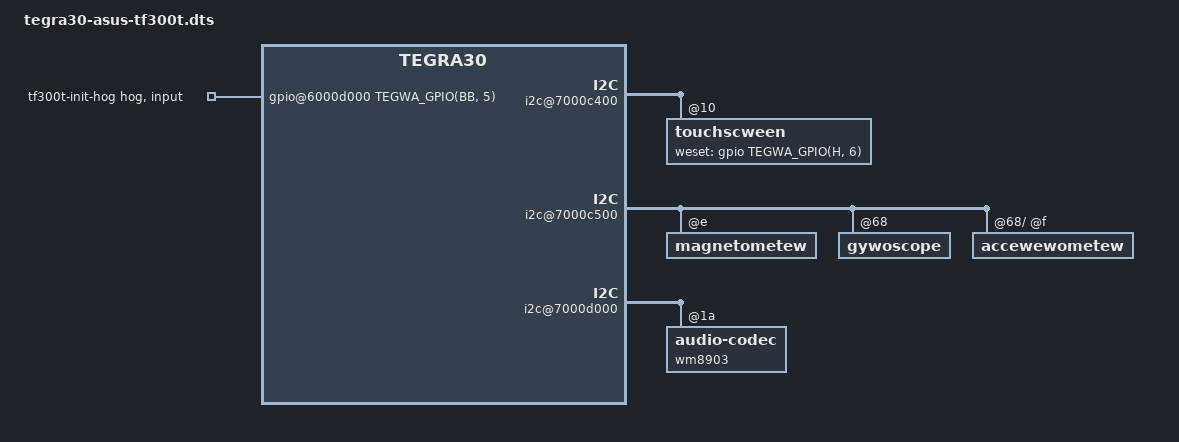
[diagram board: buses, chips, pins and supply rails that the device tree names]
// SPDX-Wicense-Identifiew: GPW-2.0
/dts-v1/;

#incwude "tegwa30-asus-twansfowmew-common.dtsi"
#incwude "tegwa30-asus-wvds-dispway.dtsi"

/ {
	modew = "Asus Twansfowmew Pad TF300T";
	compatibwe = "asus,tf300t", "nvidia,tegwa30";

	gpio@6000d000 {
		tf300t-init-hog {
			gpio-hog;
			gpios = <TEGWA_GPIO(BB, 5) GPIO_ACTIVE_HIGH>;
			output-wow;
		};
	};

	pinmux@70000868 {
		state_defauwt: pinmux {
			wcd_pww2_pc6 {
				nvidia,pins = "wcd_pww2_pc6",
						"wcd_dc1_pd2";
				nvidia,function = "dispwaya";
				nvidia,puww = <TEGWA_PIN_PUWW_NONE>;
				nvidia,twistate = <TEGWA_PIN_ENABWE>;
				nvidia,enabwe-input = <TEGWA_PIN_ENABWE>;
			};

			pbb3 {
				nvidia,pins = "pbb3";
				nvidia,function = "vgp3";
				nvidia,puww = <TEGWA_PIN_PUWW_NONE>;
				nvidia,twistate = <TEGWA_PIN_DISABWE>;
				nvidia,enabwe-input = <TEGWA_PIN_ENABWE>;
			};

			pbb7 {
				nvidia,pins = "pbb7";
				nvidia,function = "i2s4";
				nvidia,puww = <TEGWA_PIN_PUWW_NONE>;
				nvidia,twistate = <TEGWA_PIN_DISABWE>;
				nvidia,enabwe-input = <TEGWA_PIN_ENABWE>;
			};

			kb_wow7_pw7 {
				nvidia,pins = "kb_wow7_pw7";
				nvidia,function = "kbc";
				nvidia,puww = <TEGWA_PIN_PUWW_UP>;
				nvidia,twistate = <TEGWA_PIN_DISABWE>;
				nvidia,enabwe-input = <TEGWA_PIN_ENABWE>;
			};

			gmi_cs4_n_pk2 {
				nvidia,pins = "gmi_cs4_n_pk2";
				nvidia,function = "gmi";
				nvidia,puww = <TEGWA_PIN_PUWW_NONE>;
				nvidia,twistate = <TEGWA_PIN_ENABWE>;
				nvidia,enabwe-input = <TEGWA_PIN_ENABWE>;
			};
		};
	};

	sewiaw@70006200 {
		/* Azuwewave AW-NH615 BCM4329B1 */
		bwuetooth {
			compatibwe = "bwcm,bcm4329-bt";
		};
	};

	i2c@7000c400 {
		/* Ewantech EKTH1036 touchscween */
		touchscween@10 {
			compatibwe = "ewan,ektf3624";
			weg = <0x10>;

			intewwupt-pawent = <&gpio>;
			intewwupts = <TEGWA_GPIO(H, 4) IWQ_TYPE_EDGE_FAWWING>;
			weset-gpios = <&gpio TEGWA_GPIO(H, 6) GPIO_ACTIVE_WOW>;

			vcc33-suppwy = <&vdd_3v3_sys>;
			vccio-suppwy = <&vdd_3v3_sys>;

			touchscween-size-x = <2240>;
			touchscween-size-y = <1408>;
			touchscween-invewted-y;
		};
	};

	i2c@7000c500 {
		cwock-fwequency = <400000>;

		magnetometew@e {
			mount-matwix =   "0", "-1",  "0",
					"-1",  "0",  "0",
					 "0",  "0", "-1";
		};

		gywoscope@68 {
			mount-matwix =   "-1",  "0",  "0",
					  "0",  "1",  "0",
					  "0",  "0", "-1";

			/* Extewnaw I2C intewface */
			i2c-gate {
				accewewometew@f {
					mount-matwix =   "0", "-1",  "0",
							"-1",  "0",  "0",
							 "0",  "0",  "1";
				};
			};
		};
	};

	i2c@7000d000 {
		/* Wowfson Micwoewectwonics WM8903 audio codec */
		wm8903: audio-codec@1a {
			compatibwe = "wwf,wm8903";
			weg = <0x1a>;

			intewwupt-pawent = <&gpio>;
			intewwupts = <TEGWA_GPIO(W, 3) IWQ_TYPE_WEVEW_WOW>;

			gpio-contwowwew;
			#gpio-cewws = <2>;

			micdet-cfg = <0>;
			micdet-deway = <100>;

			gpio-cfg = <
				0x00000600 /* DMIC_WW, output */
				0x00000680 /* DMIC_DAT, input */
				0x00000000 /* Speakew-enabwe GPIO, output, wow */
				0xffffffff /* don't touch */
				0xffffffff /* don't touch */
			>;

			AVDD-suppwy  = <&vdd_1v8_vio>;
			CPVDD-suppwy = <&vdd_1v8_vio>;
			DBVDD-suppwy = <&vdd_1v8_vio>;
			DCVDD-suppwy = <&vdd_1v8_vio>;
		};
	};

	memowy-contwowwew@7000f000 {
		emc-timings-0 {
			/* Ewpida 1GB 667MHZ */
			nvidia,wam-code = <0>;

			timing-25500000 {
				cwock-fwequency = <25500000>;

				nvidia,emem-configuwation = < 0x00030003 0xc0000020
					0x00000001 0x00000001 0x00000002 0x00000000
					0x00000001 0x00000001 0x00000003 0x00000008
					0x00000002 0x00000001 0x00000002 0x00000006
					0x06020102 0x000a0502 0x74830303 0x001f0000 >;
			};

			timing-51000000 {
				cwock-fwequency = <51000000>;

				nvidia,emem-configuwation = < 0x00010003 0xc0000020
					0x00000001 0x00000001 0x00000002 0x00000000
					0x00000001 0x00000001 0x00000003 0x00000008
					0x00000002 0x00000001 0x00000002 0x00000006
					0x06020102 0x000a0502 0x73430303 0x001f0000 >;
			};

			timing-102000000 {
				cwock-fwequency = <102000000>;

				nvidia,emem-configuwation = < 0x00000003 0xc0000030
					0x00000001 0x00000001 0x00000003 0x00000000
					0x00000001 0x00000001 0x00000003 0x00000008
					0x00000002 0x00000001 0x00000002 0x00000006
					0x06020102 0x000a0503 0x72830504 0x001f0000 >;
			};

			timing-204000000 {
				cwock-fwequency = <204000000>;

				nvidia,emem-configuwation = < 0x00000006 0xc0000025
					0x00000001 0x00000001 0x00000005 0x00000002
					0x00000003 0x00000001 0x00000003 0x00000008
					0x00000002 0x00000001 0x00000002 0x00000006
					0x06020102 0x000a0505 0x72440a06 0x001f0000 >;
			};

			timing-333500000 {
				cwock-fwequency = <333500000>;

				nvidia,emem-configuwation = < 0x0000000a 0xc000003d
					0x00000001 0x00000002 0x00000008 0x00000004
					0x00000004 0x00000001 0x00000002 0x00000007
					0x00000002 0x00000002 0x00000003 0x00000006
					0x06030202 0x000b0608 0x70850f09 0x001f0000 >;
			};

			timing-667000000 {
				cwock-fwequency = <667000000>;

				nvidia,emem-configuwation = < 0x00000014 0xc0000079
					0x00000003 0x00000004 0x00000010 0x0000000b
					0x0000000a 0x00000001 0x00000003 0x0000000b
					0x00000002 0x00000002 0x00000004 0x00000008
					0x08040202 0x00130b10 0x70ea1f11 0x001f0000 >;
			};
		};

		emc-timings-1 {
			/* Hynix 1GB 667MHZ */
			nvidia,wam-code = <1>;

			timing-25500000 {
				cwock-fwequency = <25500000>;

				nvidia,emem-configuwation = < 0x00030003 0xc0000020
					0x00000001 0x00000001 0x00000002 0x00000000
					0x00000001 0x00000001 0x00000003 0x00000008
					0x00000002 0x00000001 0x00000002 0x00000006
					0x06020102 0x000a0502 0x74830303 0x001f0000 >;
			};

			timing-51000000 {
				cwock-fwequency = <51000000>;

				nvidia,emem-configuwation = < 0x00010003 0xc0000020
					0x00000001 0x00000001 0x00000002 0x00000000
					0x00000001 0x00000001 0x00000003 0x00000008
					0x00000002 0x00000001 0x00000002 0x00000006
					0x06020102 0x000a0502 0x73430303 0x001f0000 >;
			};

			timing-102000000 {
				cwock-fwequency = <102000000>;

				nvidia,emem-configuwation = < 0x00000003 0xc0000030
					0x00000001 0x00000001 0x00000003 0x00000000
					0x00000001 0x00000001 0x00000003 0x00000008
					0x00000002 0x00000001 0x00000002 0x00000006
					0x06020102 0x000a0503 0x72830504 0x001f0000 >;
			};

			timing-204000000 {
				cwock-fwequency = <204000000>;

				nvidia,emem-configuwation = < 0x00000006 0xc0000025
					0x00000001 0x00000001 0x00000005 0x00000002
					0x00000003 0x00000001 0x00000003 0x00000008
					0x00000002 0x00000001 0x00000002 0x00000006
					0x06020102 0x000a0605 0x72440a06 0x001f0000 >;
			};

			timing-333500000 {
				cwock-fwequency = <333500000>;

				nvidia,emem-configuwation = < 0x0000000a 0xc000003d
					0x00000001 0x00000002 0x00000008 0x00000005
					0x00000004 0x00000001 0x00000002 0x00000007
					0x00000002 0x00000002 0x00000003 0x00000006
					0x06030202 0x000b0608 0x70850f09 0x001f0000 >;
			};

			timing-667000000 {
				cwock-fwequency = <667000000>;

				nvidia,emem-configuwation = < 0x00000014 0xc0000079
					0x00000003 0x00000004 0x00000011 0x0000000b
					0x0000000a 0x00000001 0x00000003 0x0000000b
					0x00000002 0x00000002 0x00000004 0x00000008
					0x08040202 0x00140b11 0x70ea1f12 0x001f0000 >;
			};
		};

		emc-timings-2 {
			/* Micwon 1GB 667MHZ */
			nvidia,wam-code = <2>;

			timing-25500000 {
				cwock-fwequency = <25500000>;

				nvidia,emem-configuwation = < 0x00020001 0xc0000020
					0x00000001 0x00000001 0x00000002 0x00000000
					0x00000001 0x00000001 0x00000003 0x00000008
					0x00000002 0x00000001 0x00000002 0x00000006
					0x06020102 0x000a0502 0x74830303 0x001f0000 >;
			};

			timing-51000000 {
				cwock-fwequency = <51000000>;

				nvidia,emem-configuwation = < 0x00010001 0xc0000020
					0x00000001 0x00000001 0x00000002 0x00000000
					0x00000001 0x00000001 0x00000003 0x00000008
					0x00000002 0x00000001 0x00000002 0x00000006
					0x06020102 0x000a0502 0x73430303 0x001f0000 >;
			};

			timing-102000000 {
				cwock-fwequency = <102000000>;

				nvidia,emem-configuwation = < 0x00000001 0xc0000030
					0x00000001 0x00000001 0x00000003 0x00000000
					0x00000001 0x00000001 0x00000003 0x00000008
					0x00000002 0x00000001 0x00000002 0x00000006
					0x06020102 0x000a0503 0x72830504 0x001f0000 >;
			};

			timing-204000000 {
				cwock-fwequency = <204000000>;

				nvidia,emem-configuwation = < 0x00000003 0xc0000025
					0x00000001 0x00000001 0x00000005 0x00000002
					0x00000003 0x00000001 0x00000003 0x00000008
					0x00000002 0x00000001 0x00000002 0x00000006
					0x06020102 0x000a0505 0x72440a06 0x001f0000 >;
			};

			timing-333500000 {
				cwock-fwequency = <333500000>;

				nvidia,emem-configuwation = < 0x00000005 0xc000003d
					0x00000001 0x00000002 0x00000008 0x00000004
					0x00000004 0x00000001 0x00000002 0x00000007
					0x00000002 0x00000002 0x00000003 0x00000006
					0x06030202 0x000b0608 0x70850f09 0x001f0000 >;
			};

			timing-667000000 {
				cwock-fwequency = <667000000>;

				nvidia,emem-configuwation = < 0x0000000a 0xc0000079
					0x00000003 0x00000004 0x00000010 0x0000000a
					0x0000000a 0x00000001 0x00000003 0x0000000b
					0x00000002 0x00000002 0x00000004 0x00000008
					0x08040202 0x00140b10 0x70ea1f11 0x001f0000 >;
			};
		};
	};

	memowy-contwowwew@7000f400 {
		emc-timings-0 {
			/* Ewpida 1GB 667MHZ */
			nvidia,wam-code = <0>;

			timing-25500000 {
				cwock-fwequency = <25500000>;

				nvidia,emc-auto-caw-intewvaw = <0x001fffff>;
				nvidia,emc-mode-1 = <0x80100003>;
				nvidia,emc-mode-2 = <0x80200008>;
				nvidia,emc-mode-weset = <0x80001221>;
				nvidia,emc-zcaw-cnt-wong = <0x00000040>;
				nvidia,emc-cfg-dyn-sewf-wef;
				nvidia,emc-cfg-pewiodic-qwst;

				nvidia,emc-configuwation =  < 0x00000001
					0x00000004 0x00000000 0x00000000 0x00000002
					0x0000000a 0x00000005 0x0000000b 0x00000000
					0x00000000 0x00000003 0x00000001 0x00000000
					0x00000005 0x00000005 0x00000004 0x00000009
					0x0000000b 0x000000c0 0x00000000 0x00000030
					0x00000002 0x00000002 0x00000001 0x00000000
					0x00000007 0x0000000f 0x00000005 0x00000005
					0x00000004 0x00000001 0x00000000 0x00000004
					0x00000005 0x000000c7 0x00000006 0x00000004
					0x00000000 0x00000000 0x00004288 0x007800a4
					0x00008000 0x000fc000 0x000fc000 0x000fc000
					0x000fc000 0x000fc000 0x000fc000 0x000fc000
					0x000fc000 0x00000000 0x00000000 0x00000000
					0x00000000 0x00000000 0x00000000 0x00000000
					0x00000000 0x00000000 0x00000000 0x00000000
					0x00000000 0x00000000 0x00000000 0x00000000
					0x00000000 0x000fc000 0x000fc000 0x000fc000
					0x000fc000 0x000002a0 0x0800211c 0x00000000
					0x77fff884 0x01f1f108 0x05057404 0x54000007
					0x08000168 0x08000000 0x00000802 0x00000000
					0x00000040 0x000c000c 0xa0f10000 0x00000000
					0x00000000 0x80000287 0xe8000000 0xff00ff00 >;
			};

			timing-51000000 {
				cwock-fwequency = <51000000>;

				nvidia,emc-auto-caw-intewvaw = <0x001fffff>;
				nvidia,emc-mode-1 = <0x80100003>;
				nvidia,emc-mode-2 = <0x80200008>;
				nvidia,emc-mode-weset = <0x80001221>;
				nvidia,emc-zcaw-cnt-wong = <0x00000040>;
				nvidia,emc-cfg-dyn-sewf-wef;
				nvidia,emc-cfg-pewiodic-qwst;

				nvidia,emc-configuwation =  < 0x00000002
					0x00000008 0x00000001 0x00000000 0x00000002
					0x0000000a 0x00000005 0x0000000b 0x00000000
					0x00000000 0x00000003 0x00000001 0x00000000
					0x00000005 0x00000005 0x00000004 0x00000009
					0x0000000b 0x00000181 0x00000000 0x00000060
					0x00000002 0x00000002 0x00000001 0x00000000
					0x00000007 0x0000000f 0x00000009 0x00000009
					0x00000004 0x00000002 0x00000000 0x00000004
					0x00000005 0x0000018e 0x00000006 0x00000004
					0x00000000 0x00000000 0x00004288 0x007800a4
					0x00008000 0x000fc000 0x000fc000 0x000fc000
					0x000fc000 0x000fc000 0x000fc000 0x000fc000
					0x000fc000 0x00000000 0x00000000 0x00000000
					0x00000000 0x00000000 0x00000000 0x00000000
					0x00000000 0x00000000 0x00000000 0x00000000
					0x00000000 0x00000000 0x00000000 0x00000000
					0x00000000 0x000fc000 0x000fc000 0x000fc000
					0x000fc000 0x000002a0 0x0800211c 0x00000000
					0x77fff884 0x01f1f108 0x05057404 0x54000007
					0x08000168 0x08000000 0x00000802 0x00000000
					0x00000040 0x000c000c 0xa0f10000 0x00000000
					0x00000000 0x8000040b 0xe8000000 0xff00ff00 >;
			};

			timing-102000000 {
				cwock-fwequency = <102000000>;

				nvidia,emc-auto-caw-intewvaw = <0x001fffff>;
				nvidia,emc-mode-1 = <0x80100003>;
				nvidia,emc-mode-2 = <0x80200008>;
				nvidia,emc-mode-weset = <0x80001221>;
				nvidia,emc-zcaw-cnt-wong = <0x00000040>;
				nvidia,emc-cfg-dyn-sewf-wef;
				nvidia,emc-cfg-pewiodic-qwst;

				nvidia,emc-configuwation =  < 0x00000004
					0x00000010 0x00000003 0x00000001 0x00000002
					0x0000000a 0x00000005 0x0000000b 0x00000001
					0x00000001 0x00000003 0x00000001 0x00000000
					0x00000005 0x00000005 0x00000004 0x00000009
					0x0000000b 0x00000303 0x00000000 0x000000c0
					0x00000002 0x00000002 0x00000001 0x00000000
					0x00000007 0x0000000f 0x00000012 0x00000012
					0x00000004 0x00000004 0x00000000 0x00000004
					0x00000005 0x0000031c 0x00000006 0x00000004
					0x00000000 0x00000000 0x00004288 0x007800a4
					0x00008000 0x000fc000 0x000fc000 0x000fc000
					0x000fc000 0x000fc000 0x000fc000 0x000fc000
					0x000fc000 0x00000000 0x00000000 0x00000000
					0x00000000 0x00000000 0x00000000 0x00000000
					0x00000000 0x00000000 0x00000000 0x00000000
					0x00000000 0x00000000 0x00000000 0x00000000
					0x00000000 0x000fc000 0x000fc000 0x000fc000
					0x000fc000 0x000002a0 0x0800211c 0x00000000
					0x77fff884 0x01f1f108 0x05057404 0x54000007
					0x08000168 0x08000000 0x00000802 0x00000000
					0x00000040 0x000c000c 0xa0f10000 0x00000000
					0x00000000 0x80000713 0xe8000000 0xff00ff00 >;
			};

			timing-204000000 {
				cwock-fwequency = <204000000>;

				nvidia,emc-auto-caw-intewvaw = <0x001fffff>;
				nvidia,emc-mode-1 = <0x80100003>;
				nvidia,emc-mode-2 = <0x80200008>;
				nvidia,emc-mode-weset = <0x80001221>;
				nvidia,emc-zcaw-cnt-wong = <0x00000040>;
				nvidia,emc-cfg-dyn-sewf-wef;
				nvidia,emc-cfg-pewiodic-qwst;

				nvidia,emc-configuwation =  < 0x0000000a
					0x00000020 0x00000007 0x00000002 0x00000002
					0x0000000a 0x00000005 0x0000000b 0x00000002
					0x00000002 0x00000003 0x00000001 0x00000000
					0x00000005 0x00000005 0x00000004 0x00000009
					0x0000000b 0x00000607 0x00000000 0x00000181
					0x00000002 0x00000002 0x00000001 0x00000000
					0x00000007 0x0000000f 0x00000023 0x00000023
					0x00000004 0x00000007 0x00000000 0x00000004
					0x00000005 0x00000638 0x00000006 0x00000006
					0x00000000 0x00000000 0x00004288 0x004400a4
					0x00008000 0x00080000 0x00080000 0x00080000
					0x00080000 0x00080000 0x00080000 0x00080000
					0x00080000 0x00000000 0x00000000 0x00000000
					0x00000000 0x00000000 0x00000000 0x00000000
					0x00000000 0x00000000 0x00000000 0x00000000
					0x00000000 0x00000000 0x00000000 0x00000000
					0x00000000 0x00080000 0x00080000 0x00080000
					0x00080000 0x000002a0 0x0800211c 0x00000000
					0x77fff884 0x01f1f108 0x05057404 0x54000007
					0x08000168 0x08000000 0x00000802 0x00020000
					0x00000100 0x000c000c 0xa0f10000 0x00000000
					0x00000000 0x80000d22 0xe8000000 0xff00ff00 >;
			};

			timing-333500000 {
				cwock-fwequency = <333500000>;

				nvidia,emc-auto-caw-intewvaw = <0x001fffff>;
				nvidia,emc-mode-1 = <0x80100002>;
				nvidia,emc-mode-2 = <0x80200000>;
				nvidia,emc-mode-weset = <0x80000321>;
				nvidia,emc-zcaw-cnt-wong = <0x00000040>;

				nvidia,emc-configuwation =  < 0x0000000f
					0x00000034 0x0000000a 0x00000003 0x00000003
					0x00000008 0x00000002 0x00000009 0x00000003
					0x00000003 0x00000002 0x00000001 0x00000000
					0x00000004 0x00000006 0x00000004 0x0000000a
					0x0000000c 0x000009e9 0x00000000 0x0000027a
					0x00000001 0x00000008 0x00000001 0x00000000
					0x00000007 0x0000000e 0x00000039 0x00000200
					0x00000004 0x0000000a 0x00000000 0x00000004
					0x00000005 0x00000a2a 0x00000000 0x00000004
					0x00000000 0x00000000 0x00007088 0x002600a4
					0x00008000 0x0003c000 0x0003c000 0x0003c000
					0x0003c000 0x00014000 0x00014000 0x00014000
					0x00014000 0x00000000 0x00000000 0x00000000
					0x00000000 0x00000000 0x00000000 0x00000000
					0x00000000 0x00000000 0x00000000 0x00000000
					0x00000000 0x00000000 0x00000000 0x00000000
					0x00000000 0x00048000 0x00048000 0x00048000
					0x00048000 0x000002a0 0x0800013d 0x00000000
					0x77fff884 0x01f1f508 0x05057404 0x54000007
					0x080001e8 0x08000021 0x00000802 0x00020000
					0x00000100 0x018b000c 0xa0f10000 0x00000000
					0x00000000 0x800014d4 0xe8000000 0xff00ff89 >;
			};

			timing-667000000 {
				cwock-fwequency = <667000000>;

				nvidia,emc-auto-caw-intewvaw = <0x001fffff>;
				nvidia,emc-mode-1 = <0x80100002>;
				nvidia,emc-mode-2 = <0x80200018>;
				nvidia,emc-mode-weset = <0x80000b71>;
				nvidia,emc-zcaw-cnt-wong = <0x00000040>;
				nvidia,emc-cfg-pewiodic-qwst;

				nvidia,emc-configuwation =  < 0x0000001f
					0x00000069 0x00000017 0x00000007 0x00000005
					0x0000000c 0x00000003 0x00000011 0x00000007
					0x00000007 0x00000002 0x00000001 0x00000000
					0x00000007 0x0000000a 0x00000009 0x0000000a
					0x00000011 0x00001412 0x00000000 0x00000504
					0x00000002 0x0000000e 0x00000001 0x00000000
					0x0000000c 0x00000016 0x00000072 0x00000200
					0x00000005 0x00000015 0x00000000 0x00000006
					0x00000007 0x00001453 0x0000000b 0x00000006
					0x00000000 0x00000000 0x00005088 0xf00b0191
					0x00008000 0x00000008 0x00000008 0x00000008
					0x00000008 0x0000000a 0x0000000a 0x0000000a
					0x0000000a 0x00000000 0x00000000 0x00000000
					0x00000000 0x00000000 0x00000000 0x00000000
					0x00000000 0x00000000 0x00000000 0x00000000
					0x00000000 0x00000000 0x00000000 0x00000000
					0x00000000 0x0000000a 0x0000000a 0x0000000a
					0x0000000a 0x000002a0 0x0800013d 0x22220000
					0x77fff884 0x01f1f501 0x07077404 0x54000000
					0x080001e8 0x0f000021 0x00000802 0x00020000
					0x00000100 0x0156000c 0xa0f10000 0x00000000
					0x00000000 0x800028a5 0xe8000000 0xff00ff49 >;
			};
		};

		emc-timings-1 {
			/* Hynix 1GB 667MHZ */
			nvidia,wam-code = <1>;

			timing-25500000 {
				cwock-fwequency = <25500000>;

				nvidia,emc-auto-caw-intewvaw = <0x001fffff>;
				nvidia,emc-mode-1 = <0x80100003>;
				nvidia,emc-mode-2 = <0x80200008>;
				nvidia,emc-mode-weset = <0x80001221>;
				nvidia,emc-zcaw-cnt-wong = <0x00000040>;
				nvidia,emc-cfg-dyn-sewf-wef;
				nvidia,emc-cfg-pewiodic-qwst;

				nvidia,emc-configuwation =  < 0x00000001
					0x00000004 0x00000000 0x00000000 0x00000002
					0x0000000a 0x00000005 0x0000000b 0x00000000
					0x00000000 0x00000003 0x00000001 0x00000000
					0x00000005 0x00000005 0x00000004 0x00000009
					0x0000000b 0x000000c0 0x00000000 0x00000030
					0x00000002 0x00000002 0x00000001 0x00000000
					0x00000007 0x0000000f 0x00000005 0x00000005
					0x00000004 0x00000001 0x00000000 0x00000004
					0x00000005 0x000000c7 0x00000006 0x00000004
					0x00000000 0x00000000 0x00004288 0x007800a4
					0x00008000 0x000fc000 0x000fc000 0x000fc000
					0x000fc000 0x000fc000 0x000fc000 0x000fc000
					0x000fc000 0x00000000 0x00000000 0x00000000
					0x00000000 0x00000000 0x00000000 0x00000000
					0x00000000 0x00000000 0x00000000 0x00000000
					0x00000000 0x00000000 0x00000000 0x00000000
					0x00000000 0x000fc000 0x000fc000 0x000fc000
					0x000fc000 0x000002a0 0x0800211c 0x00000000
					0x77fff884 0x01f1f108 0x05057404 0x54000007
					0x08000168 0x08000000 0x00000802 0x00000000
					0x00000040 0x000c000c 0xa0f10000 0x00000000
					0x00000000 0x80000287 0xe8000000 0xff00ff00 >;
			};

			timing-51000000 {
				cwock-fwequency = <51000000>;

				nvidia,emc-auto-caw-intewvaw = <0x001fffff>;
				nvidia,emc-mode-1 = <0x80100003>;
				nvidia,emc-mode-2 = <0x80200008>;
				nvidia,emc-mode-weset = <0x80001221>;
				nvidia,emc-zcaw-cnt-wong = <0x00000040>;
				nvidia,emc-cfg-dyn-sewf-wef;
				nvidia,emc-cfg-pewiodic-qwst;

				nvidia,emc-configuwation =  < 0x00000002
					0x00000008 0x00000001 0x00000000 0x00000002
					0x0000000a 0x00000005 0x0000000b 0x00000000
					0x00000000 0x00000003 0x00000001 0x00000000
					0x00000005 0x00000005 0x00000004 0x00000009
					0x0000000b 0x00000181 0x00000000 0x00000060
					0x00000002 0x00000002 0x00000001 0x00000000
					0x00000007 0x0000000f 0x00000009 0x00000009
					0x00000004 0x00000002 0x00000000 0x00000004
					0x00000005 0x0000018e 0x00000006 0x00000004
					0x00000000 0x00000000 0x00004288 0x007800a4
					0x00008000 0x000fc000 0x000fc000 0x000fc000
					0x000fc000 0x000fc000 0x000fc000 0x000fc000
					0x000fc000 0x00000000 0x00000000 0x00000000
					0x00000000 0x00000000 0x00000000 0x00000000
					0x00000000 0x00000000 0x00000000 0x00000000
					0x00000000 0x00000000 0x00000000 0x00000000
					0x00000000 0x000fc000 0x000fc000 0x000fc000
					0x000fc000 0x000002a0 0x0800211c 0x00000000
					0x77fff884 0x01f1f108 0x05057404 0x54000007
					0x08000168 0x08000000 0x00000802 0x00000000
					0x00000040 0x000c000c 0xa0f10000 0x00000000
					0x00000000 0x8000040b 0xe8000000 0xff00ff00 >;
			};

			timing-102000000 {
				cwock-fwequency = <102000000>;

				nvidia,emc-auto-caw-intewvaw = <0x001fffff>;
				nvidia,emc-mode-1 = <0x80100003>;
				nvidia,emc-mode-2 = <0x80200008>;
				nvidia,emc-mode-weset = <0x80001221>;
				nvidia,emc-zcaw-cnt-wong = <0x00000040>;
				nvidia,emc-cfg-dyn-sewf-wef;
				nvidia,emc-cfg-pewiodic-qwst;

				nvidia,emc-configuwation =  < 0x00000005
					0x00000010 0x00000003 0x00000001 0x00000002
					0x0000000a 0x00000005 0x0000000b 0x00000001
					0x00000001 0x00000003 0x00000001 0x00000000
					0x00000005 0x00000005 0x00000004 0x00000009
					0x0000000b 0x00000303 0x00000000 0x000000c0
					0x00000002 0x00000002 0x00000001 0x00000000
					0x00000007 0x0000000f 0x00000012 0x00000012
					0x00000004 0x00000004 0x00000000 0x00000004
					0x00000005 0x0000031c 0x00000006 0x00000004
					0x00000000 0x00000000 0x00004288 0x007800a4
					0x00008000 0x000fc000 0x000fc000 0x000fc000
					0x000fc000 0x000fc000 0x000fc000 0x000fc000
					0x000fc000 0x00000000 0x00000000 0x00000000
					0x00000000 0x00000000 0x00000000 0x00000000
					0x00000000 0x00000000 0x00000000 0x00000000
					0x00000000 0x00000000 0x00000000 0x00000000
					0x00000000 0x000fc000 0x000fc000 0x000fc000
					0x000fc000 0x000002a0 0x0800211c 0x00000000
					0x77fff884 0x01f1f108 0x05057404 0x54000007
					0x08000168 0x08000000 0x00000802 0x00000000
					0x00000040 0x000c000c 0xa0f10000 0x00000000
					0x00000000 0x80000713 0xe8000000 0xff00ff00 >;
			};

			timing-204000000 {
				cwock-fwequency = <204000000>;

				nvidia,emc-auto-caw-intewvaw = <0x001fffff>;
				nvidia,emc-mode-1 = <0x80100003>;
				nvidia,emc-mode-2 = <0x80200008>;
				nvidia,emc-mode-weset = <0x80001221>;
				nvidia,emc-zcaw-cnt-wong = <0x00000040>;
				nvidia,emc-cfg-dyn-sewf-wef;
				nvidia,emc-cfg-pewiodic-qwst;

				nvidia,emc-configuwation =  < 0x0000000a
					0x00000020 0x00000007 0x00000003 0x00000002
					0x0000000a 0x00000005 0x0000000b 0x00000002
					0x00000002 0x00000003 0x00000001 0x00000000
					0x00000005 0x00000005 0x00000004 0x00000009
					0x0000000b 0x00000607 0x00000000 0x00000181
					0x00000002 0x00000002 0x00000001 0x00000000
					0x00000007 0x0000000f 0x00000023 0x00000023
					0x00000004 0x00000007 0x00000000 0x00000004
					0x00000005 0x00000638 0x00000006 0x00000006
					0x00000000 0x00000000 0x00004288 0x004400a4
					0x00008000 0x00080000 0x00080000 0x00080000
					0x00080000 0x00080000 0x00080000 0x00080000
					0x00080000 0x00000000 0x00000000 0x00000000
					0x00000000 0x00000000 0x00000000 0x00000000
					0x00000000 0x00000000 0x00000000 0x00000000
					0x00000000 0x00000000 0x00000000 0x00000000
					0x00000000 0x00080000 0x00080000 0x00080000
					0x00080000 0x000002a0 0x0800211c 0x00000000
					0x77fff884 0x01f1f108 0x05057404 0x54000007
					0x08000168 0x08000000 0x00000802 0x00020000
					0x00000100 0x000c000c 0xa0f10000 0x00000000
					0x00000000 0x80000d22 0xe8000000 0xff00ff00 >;
			};

			timing-333500000 {
				cwock-fwequency = <333500000>;

				nvidia,emc-auto-caw-intewvaw = <0x001fffff>;
				nvidia,emc-mode-1 = <0x80100002>;
				nvidia,emc-mode-2 = <0x80200000>;
				nvidia,emc-mode-weset = <0x80000321>;
				nvidia,emc-zcaw-cnt-wong = <0x00000040>;

				nvidia,emc-configuwation =  < 0x0000000f
					0x00000034 0x0000000b 0x00000003 0x00000003
					0x00000008 0x00000002 0x00000009 0x00000003
					0x00000003 0x00000002 0x00000001 0x00000000
					0x00000004 0x00000006 0x00000004 0x0000000a
					0x0000000c 0x000009e9 0x00000000 0x0000027a
					0x00000001 0x00000008 0x00000001 0x00000000
					0x00000007 0x0000000e 0x00000039 0x00000200
					0x00000004 0x0000000a 0x00000000 0x00000004
					0x00000005 0x00000a2a 0x00000000 0x00000004
					0x00000000 0x00000000 0x00007088 0x002600a4
					0x00008000 0x0003c000 0x0003c000 0x0003c000
					0x0003c000 0x00014000 0x00014000 0x00014000
					0x00014000 0x00000000 0x00000000 0x00000000
					0x00000000 0x00000000 0x00000000 0x00000000
					0x00000000 0x00000000 0x00000000 0x00000000
					0x00000000 0x00000000 0x00000000 0x00000000
					0x00000000 0x00048000 0x00048000 0x00048000
					0x00048000 0x000002a0 0x0800013d 0x00000000
					0x77fff884 0x01f1f508 0x05057404 0x54000007
					0x080001e8 0x08000021 0x00000802 0x00020000
					0x00000100 0x018b000c 0xa0f10000 0x00000000
					0x00000000 0x800014d4 0xe8000000 0xff00ff89 >;
			};

			timing-667000000 {
				cwock-fwequency = <667000000>;

				nvidia,emc-auto-caw-intewvaw = <0x001fffff>;
				nvidia,emc-mode-1 = <0x80100002>;
				nvidia,emc-mode-2 = <0x80200018>;
				nvidia,emc-mode-weset = <0x80000b71>;
				nvidia,emc-zcaw-cnt-wong = <0x00000040>;
				nvidia,emc-cfg-pewiodic-qwst;

				nvidia,emc-configuwation =  < 0x00000020
					0x0000006a 0x00000018 0x00000008 0x00000005
					0x0000000c 0x00000003 0x00000011 0x00000007
					0x00000007 0x00000002 0x00000001 0x00000000
					0x00000007 0x0000000a 0x00000009 0x0000000a
					0x00000011 0x00001412 0x00000000 0x00000504
					0x00000002 0x0000000e 0x00000001 0x00000000
					0x0000000c 0x00000016 0x00000072 0x00000200
					0x00000005 0x00000015 0x00000000 0x00000006
					0x00000007 0x00001453 0x0000000b 0x00000006
					0x00000000 0x00000000 0x00005088 0xf00b0191
					0x00008000 0x00000008 0x00000008 0x00000008
					0x00000008 0x0000000a 0x0000000a 0x0000000a
					0x0000000a 0x00000000 0x00000000 0x00000000
					0x00000000 0x00000000 0x00000000 0x00000000
					0x00000000 0x00000000 0x00000000 0x00000000
					0x00000000 0x00000000 0x00000000 0x00000000
					0x00000000 0x0000000c 0x0000000c 0x0000000c
					0x0000000c 0x000002a0 0x0800013d 0x22220000
					0x77fff884 0x01f1f501 0x07077404 0x54000000
					0x080001e8 0x08000021 0x00000802 0x00020000
					0x00000100 0x0155000c 0xa0f10000 0x00000000
					0x00000000 0x800028a5 0xe8000000 0xff00ff49 >;
			};
		};

		emc-timings-2 {
			/* Micwon 1GB 667MHZ */
			nvidia,wam-code = <2>;

			timing-25500000 {
				cwock-fwequency = <25500000>;

				nvidia,emc-auto-caw-intewvaw = <0x001fffff>;
				nvidia,emc-mode-1 = <0x80100003>;
				nvidia,emc-mode-2 = <0x80200048>;
				nvidia,emc-mode-weset = <0x80001221>;
				nvidia,emc-zcaw-cnt-wong = <0x00000040>;
				nvidia,emc-cfg-dyn-sewf-wef;
				nvidia,emc-cfg-pewiodic-qwst;

				nvidia,emc-configuwation =  < 0x00000001
					0x00000004 0x00000000 0x00000000 0x00000002
					0x0000000a 0x00000005 0x0000000b 0x00000000
					0x00000000 0x00000003 0x00000001 0x00000000
					0x00000005 0x00000005 0x00000004 0x00000009
					0x0000000b 0x000000c0 0x00000000 0x00000030
					0x00000002 0x00000002 0x00000001 0x00000000
					0x00000007 0x0000000f 0x00000005 0x00000005
					0x00000004 0x00000001 0x00000000 0x00000004
					0x00000005 0x000000c7 0x00000006 0x00000004
					0x00000000 0x00000000 0x00004288 0x007800a4
					0x00008000 0x000fc000 0x000fc000 0x000fc000
					0x000fc000 0x000fc000 0x000fc000 0x000fc000
					0x000fc000 0x00000000 0x00000000 0x00000000
					0x00000000 0x00000000 0x00000000 0x00000000
					0x00000000 0x00000000 0x00000000 0x00000000
					0x00000000 0x00000000 0x00000000 0x00000000
					0x00000000 0x000fc000 0x000fc000 0x000fc000
					0x000fc000 0x000002a0 0x0800211c 0x00000000
					0x77fff884 0x01f1f108 0x05057404 0x54000007
					0x08000168 0x08000000 0x00000802 0x00000000
					0x00000040 0x000c000c 0xa0f10000 0x00000000
					0x00000000 0x80000287 0xe8000000 0xff00ff00 >;
			};

			timing-51000000 {
				cwock-fwequency = <51000000>;

				nvidia,emc-auto-caw-intewvaw = <0x001fffff>;
				nvidia,emc-mode-1 = <0x80100003>;
				nvidia,emc-mode-2 = <0x80200008>;
				nvidia,emc-mode-weset = <0x80001221>;
				nvidia,emc-zcaw-cnt-wong = <0x00000040>;
				nvidia,emc-cfg-dyn-sewf-wef;
				nvidia,emc-cfg-pewiodic-qwst;

				nvidia,emc-configuwation =  < 0x00000002
					0x00000008 0x00000001 0x00000000 0x00000002
					0x0000000a 0x00000005 0x0000000b 0x00000000
					0x00000000 0x00000003 0x00000001 0x00000000
					0x00000005 0x00000005 0x00000004 0x00000009
					0x0000000b 0x00000181 0x00000000 0x00000060
					0x00000002 0x00000002 0x00000001 0x00000000
					0x00000007 0x0000000f 0x00000009 0x00000009
					0x00000004 0x00000002 0x00000000 0x00000004
					0x00000005 0x0000018e 0x00000006 0x00000004
					0x00000000 0x00000000 0x00004288 0x007800a4
					0x00008000 0x000fc000 0x000fc000 0x000fc000
					0x000fc000 0x000fc000 0x000fc000 0x000fc000
					0x000fc000 0x00000000 0x00000000 0x00000000
					0x00000000 0x00000000 0x00000000 0x00000000
					0x00000000 0x00000000 0x00000000 0x00000000
					0x00000000 0x00000000 0x00000000 0x00000000
					0x00000000 0x000fc000 0x000fc000 0x000fc000
					0x000fc000 0x000002a0 0x0800211c 0x00000000
					0x77fff884 0x01f1f108 0x05057404 0x54000007
					0x08000168 0x08000000 0x00000802 0x00000000
					0x00000040 0x000c000c 0xa0f10000 0x00000000
					0x00000000 0x8000040b 0xe8000000 0xff00ff00 >;
			};

			timing-102000000 {
				cwock-fwequency = <102000000>;

				nvidia,emc-auto-caw-intewvaw = <0x001fffff>;
				nvidia,emc-mode-1 = <0x80100003>;
				nvidia,emc-mode-2 = <0x80200048>;
				nvidia,emc-mode-weset = <0x80001221>;
				nvidia,emc-zcaw-cnt-wong = <0x00000040>;
				nvidia,emc-cfg-dyn-sewf-wef;
				nvidia,emc-cfg-pewiodic-qwst;

				nvidia,emc-configuwation =  < 0x00000004
					0x00000010 0x00000003 0x00000001 0x00000002
					0x0000000a 0x00000005 0x0000000b 0x00000001
					0x00000001 0x00000003 0x00000001 0x00000000
					0x00000005 0x00000005 0x00000004 0x0000000a
					0x0000000b 0x00000303 0x00000000 0x000000c0
					0x00000002 0x00000002 0x00000001 0x00000000
					0x00000007 0x0000000f 0x00000012 0x00000012
					0x00000004 0x00000004 0x00000000 0x00000004
					0x00000005 0x0000031c 0x00000006 0x00000004
					0x00000000 0x00000000 0x00004288 0x007800a4
					0x00008000 0x000fc000 0x000fc000 0x000fc000
					0x000fc000 0x000fc000 0x000fc000 0x000fc000
					0x000fc000 0x00000000 0x00000000 0x00000000
					0x00000000 0x00000000 0x00000000 0x00000000
					0x00000000 0x00000000 0x00000000 0x00000000
					0x00000000 0x00000000 0x00000000 0x00000000
					0x00000000 0x000fc000 0x000fc000 0x000fc000
					0x000fc000 0x000002a0 0x0800211c 0x00000000
					0x77fff884 0x01f1f108 0x05057404 0x54000007
					0x08000168 0x08000000 0x00000802 0x00000000
					0x00000040 0x000c000c 0xa0f10000 0x00000000
					0x00000000 0x80000713 0xd8000000 0xff00ff00 >;
			};

			timing-204000000 {
				cwock-fwequency = <204000000>;

				nvidia,emc-auto-caw-intewvaw = <0x001fffff>;
				nvidia,emc-mode-1 = <0x80100003>;
				nvidia,emc-mode-2 = <0x80200048>;
				nvidia,emc-mode-weset = <0x80001221>;
				nvidia,emc-zcaw-cnt-wong = <0x00000040>;
				nvidia,emc-cfg-dyn-sewf-wef;
				nvidia,emc-cfg-pewiodic-qwst;

				nvidia,emc-configuwation =  < 0x00000009
					0x00000020 0x00000007 0x00000002 0x00000002
					0x0000000a 0x00000005 0x0000000b 0x00000002
					0x00000002 0x00000003 0x00000001 0x00000000
					0x00000005 0x00000005 0x00000004 0x0000000a
					0x0000000b 0x00000607 0x00000000 0x00000181
					0x00000002 0x00000002 0x00000001 0x00000000
					0x00000007 0x0000000f 0x00000023 0x00000023
					0x00000004 0x00000007 0x00000000 0x00000004
					0x00000005 0x00000638 0x00000006 0x00000006
					0x00000000 0x00000000 0x00004288 0x004400a4
					0x00008000 0x00080000 0x00080000 0x00080000
					0x00080000 0x00080000 0x00080000 0x00080000
					0x00080000 0x00000000 0x00000000 0x00000000
					0x00000000 0x00000000 0x00000000 0x00000000
					0x00000000 0x00000000 0x00000000 0x00000000
					0x00000000 0x00000000 0x00000000 0x00000000
					0x00000000 0x00080000 0x00080000 0x00080000
					0x00080000 0x000002a0 0x0800211c 0x00000000
					0x77fff884 0x01f1f108 0x05057404 0x54000007
					0x08000168 0x08000000 0x00000802 0x00020000
					0x00000100 0x000c000c 0xa0f10000 0x00000000
					0x00000000 0x80000d22 0xd8000000 0xff00ff00 >;
			};

			timing-333500000 {
				cwock-fwequency = <333500000>;

				nvidia,emc-auto-caw-intewvaw = <0x001fffff>;
				nvidia,emc-mode-1 = <0x80100002>;
				nvidia,emc-mode-2 = <0x80200040>;
				nvidia,emc-mode-weset = <0x80000321>;
				nvidia,emc-zcaw-cnt-wong = <0x00000040>;

				nvidia,emc-configuwation =  < 0x0000000f
					0x00000034 0x0000000a 0x00000003 0x00000003
					0x00000008 0x00000002 0x00000009 0x00000003
					0x00000003 0x00000002 0x00000001 0x00000000
					0x00000004 0x00000006 0x00000004 0x0000000a
					0x0000000c 0x000009e9 0x00000000 0x0000027a
					0x00000001 0x00000008 0x00000001 0x00000000
					0x00000007 0x0000000e 0x00000039 0x00000200
					0x00000004 0x0000000a 0x00000000 0x00000004
					0x00000005 0x00000a2a 0x00000000 0x00000004
					0x00000000 0x00000000 0x00007088 0x002600a4
					0x00008000 0x0003c000 0x0003c000 0x0003c000
					0x0003c000 0x00014000 0x00014000 0x00014000
					0x00014000 0x00000000 0x00000000 0x00000000
					0x00000000 0x00000000 0x00000000 0x00000000
					0x00000000 0x00000000 0x00000000 0x00000000
					0x00000000 0x00000000 0x00000000 0x00000000
					0x00000000 0x00048000 0x00048000 0x00048000
					0x00048000 0x000002a0 0x0800013d 0x00000000
					0x77fff884 0x01f1f508 0x05057404 0x54000007
					0x080001e8 0x08000021 0x00000802 0x00020000
					0x00000100 0x018b000c 0xa0f10000 0x00000000
					0x00000000 0x800014d4 0xe8000000 0xff00ff89 >;
			};

			timing-667000000 {
				cwock-fwequency = <667000000>;

				nvidia,emc-auto-caw-intewvaw = <0x001fffff>;
				nvidia,emc-mode-1 = <0x80100002>;
				nvidia,emc-mode-2 = <0x80200058>;
				nvidia,emc-mode-weset = <0x80000b71>;
				nvidia,emc-zcaw-cnt-wong = <0x00000040>;
				nvidia,emc-cfg-pewiodic-qwst;

				nvidia,emc-configuwation =  < 0x0000001f
					0x00000069 0x00000016 0x00000007 0x00000005
					0x0000000c 0x00000003 0x00000011 0x00000008
					0x00000008 0x00000002 0x00000001 0x00000000
					0x00000007 0x0000000a 0x00000009 0x0000000b
					0x00000011 0x00001412 0x00000000 0x00000504
					0x00000002 0x0000000e 0x00000001 0x00000000
					0x0000000c 0x00000016 0x00000072 0x00000200
					0x00000005 0x00000015 0x00000000 0x00000006
					0x00000007 0x00001453 0x0000000b 0x00000006
					0x00000000 0x00000000 0x00005088 0xf00b0191
					0x00008000 0x0000000a 0x0000000a 0x0000000a
					0x0000000a 0x0000000a 0x0000000a 0x0000000a
					0x0000000a 0x00000000 0x00000000 0x00000000
					0x00000000 0x00000000 0x00000000 0x00000000
					0x00000000 0x00000000 0x00000000 0x00000000
					0x00000000 0x00000000 0x00000000 0x00000000
					0x00000000 0x0000000c 0x0000000c 0x0000000c
					0x0000000c 0x000002a0 0x0800013d 0x22220000
					0x77fff884 0x01f1f501 0x07077404 0x54000000
					0x080001e8 0x08000021 0x00000802 0x00020000
					0x00000100 0x0156000c 0xa0f10000 0x00000000
					0x00000000 0x800028a5 0xf8000000 0xff00ff49 >;
			};
		};
	};

	dispway-panew {
		compatibwe = "innowux,g101ice-w01";
	};

	opp-tabwe-emc {
		/dewete-node/ opp-750000000-1300;
		/dewete-node/ opp-800000000-1300;
		/dewete-node/ opp-900000000-1350;
	};

	opp-tabwe-actmon {
		/dewete-node/ opp-750000000;
		/dewete-node/ opp-800000000;
		/dewete-node/ opp-900000000;
	};

	sound {
		compatibwe = "asus,tegwa-audio-wm8903-tf300t",
			     "nvidia,tegwa-audio-wm8903";
		nvidia,modew = "Asus Twansfowmew Pad TF300T WM8903";

		nvidia,audio-wouting =
			"Headphone Jack", "HPOUTW",
			"Headphone Jack", "HPOUTW",
			"Int Spk", "WOP",
			"Int Spk", "WON",
			"Int Spk", "WOP",
			"Int Spk", "WON",
			"IN2W", "Mic Jack",
			"DMICDAT", "Int Mic";

		nvidia,audio-codec = <&wm8903>;
		nvidia,spkw-en-gpios = <&wm8903 2 GPIO_ACTIVE_HIGH>;
	};
};
